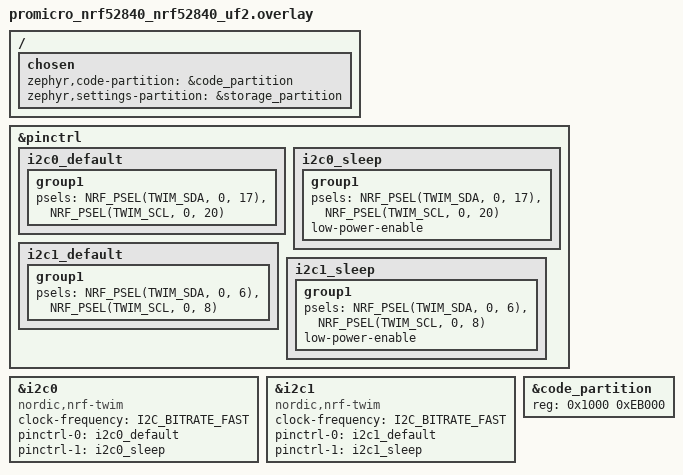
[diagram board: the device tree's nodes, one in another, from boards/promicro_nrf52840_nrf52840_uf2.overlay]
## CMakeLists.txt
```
#
# Copyright (c) 2019 Nordic Semiconductor ASA
#
# SPDX-License-Identifier: LicenseRef-Nordic-5-Clause
#
cmake_minimum_required(VERSION 3.20.0)

find_package(Zephyr REQUIRED HINTS $ENV{ZEPHYR_BASE})
project(peripheral_hids_mouse_Toast)

# Add all source files
target_sources(app PRIVATE
    src/main.c
    src/hid.c
    src/bluetooth.c
    src/encoder.c

)

target_include_directories(app PRIVATE src)
```

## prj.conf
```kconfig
#
# Copyright (c) 2019 Nordic Semiconductor ASA
#
# SPDX-License-Identifier: LicenseRef-Nordic-5-Clause
#
CONFIG_NCS_SAMPLES_DEFAULTS=y

CONFIG_BT=y
CONFIG_BT_MAX_CONN=2
CONFIG_BT_MAX_PAIRED=2
CONFIG_BT_ATT_TX_COUNT=5
CONFIG_BT_PERIPHERAL=y
CONFIG_BT_DEVICE_NAME="Wenke_Paddles"
CONFIG_BT_DEVICE_APPEARANCE=962

CONFIG_BT_BAS=y
CONFIG_BT_HIDS=y
CONFIG_BT_HIDS_MAX_CLIENT_COUNT=2
CONFIG_BT_HIDS_DEFAULT_PERM_RW_ENCRYPT=y
CONFIG_BT_GATT_UUID16_POOL_SIZE=40
CONFIG_BT_GATT_CHRC_POOL_SIZE=20

CONFIG_BT_CONN_CTX=y

CONFIG_BT_DIS=y
CONFIG_BT_DIS_MANUF_NAME=y
CONFIG_BT_DIS_MANUF_NAME_STR="NordicSemiconductor"
CONFIG_BT_DIS_PNP=y
CONFIG_BT_DIS_PNP_VID_SRC=2
CONFIG_BT_DIS_PNP_VID=0x1915
CONFIG_BT_DIS_PNP_PID=0xEEEE
CONFIG_BT_DIS_PNP_VER=0x0100

CONFIG_MAIN_STACK_SIZE=2048
CONFIG_SYSTEM_WORKQUEUE_STACK_SIZE=2048

# SERIAL LOGGING
CONFIG_SERIAL=y
CONFIG_UART_CONSOLE=y
CONFIG_CONSOLE=y#
# Copyright (c) 2019 Nordic Semiconductor ASA
#
# SPDX-License-Identifier: LicenseRef-Nordic-5-Clause
#
CONFIG_NCS_SAMPLES_DEFAULTS=y

CONFIG_BT=y
CONFIG_BT_MAX_CONN=1
CONFIG_BT_MAX_PAIRED=2
CONFIG_BT_ATT_TX_COUNT=5
CONFIG_BT_PERIPHERAL=y
CONFIG_BT_DEVICE_NAME="Wenke_Wheel"
CONFIG_BT_DEVICE_APPEARANCE=962

CONFIG_BT_BAS=y
CONFIG_BT_HIDS=y
CONFIG_BT_HIDS_MAX_CLIENT_COUNT=1
CONFIG_BT_HIDS_DEFAULT_PERM_RW_ENCRYPT=y
CONFIG_BT_GATT_UUID16_POOL_SIZE=40
CONFIG_BT_GATT_CHRC_POOL_SIZE=20

CONFIG_BT_CONN_CTX=y

CONFIG_BT_DIS=y
CONFIG_BT_DIS_MANUF_NAME=y
CONFIG_BT_DIS_MANUF_NAME_STR="NordicSemiconductor"
CONFIG_BT_DIS_PNP=y
CONFIG_BT_DIS_PNP_VID_SRC=2
CONFIG_BT_DIS_PNP_VID=0x1915
CONFIG_BT_DIS_PNP_PID=0xEEEE
CONFIG_BT_DIS_PNP_VER=0x0100

CONFIG_MAIN_STACK_SIZE=2048
CONFIG_SYSTEM_WORKQUEUE_STACK_SIZE=2048


# SERIAL LOGGING
CONFIG_SERIAL=y
CONFIG_UART_CONSOLE=y
CONFIG_CONSOLE=y
CONFIG_LOG=y
CONFIG_LOG_BACKEND_UART=y
CONFIG_LOG_DEFAULT_LEVEL=3
CONFIG_USB_CDC_ACM=y
CONFIG_USB_COMPOSITE_DEVICE=y
# ##############

# I2C CONFIGS
CONFIG_I2C=y
CONFIG_GPIO=y
CONFIG_LOG=y
CONFIG_LOG_BACKEND_UART=y
CONFIG_LOG_DEFAULT_LEVEL=3
CONFIG_USB_CDC_ACM=y
CONFIG_USB_COMPOSITE_DEVICE=y
# ##############

# I2C CONFIGS
CONFIG_I2C=y
CONFIG_GPIO=y
```

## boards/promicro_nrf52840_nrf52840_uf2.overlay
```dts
/* I2C0 - First encoder: SDA P0.17, SCL P0.20 */
&pinctrl {
    i2c0_default: i2c0_default {
        group1 {
            psels = <NRF_PSEL(TWIM_SDA, 0, 17)>,
                    <NRF_PSEL(TWIM_SCL, 0, 20)>;
        };
    };

    i2c0_sleep: i2c0_sleep {
        group1 {
            psels = <NRF_PSEL(TWIM_SDA, 0, 17)>,
                    <NRF_PSEL(TWIM_SCL, 0, 20)>;
            low-power-enable;
        };
    };

    /* I2C1 - Second encoder: SDA P0.06, SCL P0.08 */
    i2c1_default: i2c1_default {
        group1 {
            psels = <NRF_PSEL(TWIM_SDA, 0, 6)>,
                    <NRF_PSEL(TWIM_SCL, 0, 8)>;
        };
    };

    i2c1_sleep: i2c1_sleep {
        group1 {
            psels = <NRF_PSEL(TWIM_SDA, 0, 6)>,
                    <NRF_PSEL(TWIM_SCL, 0, 8)>;
            low-power-enable;
        };
    };
};

&i2c0 {
    compatible = "nordic,nrf-twim";
    status = "okay";
    clock-frequency = <I2C_BITRATE_FAST>;
    pinctrl-0 = <&i2c0_default>;
    pinctrl-1 = <&i2c0_sleep>;
    pinctrl-names = "default", "sleep";
};

&i2c1 {
    compatible = "nordic,nrf-twim";
    status = "okay";
    clock-frequency = <I2C_BITRATE_FAST>;
    pinctrl-0 = <&i2c1_default>;
    pinctrl-1 = <&i2c1_sleep>;
    pinctrl-names = "default", "sleep";
};

/* Remove the SoftDevice partition and fix the code partition offset */
/delete-node/ &reserved_partition_0;

&code_partition {
    reg = <0x1000 0xEB000>;  /* Start at 0x1000 instead of 0x26000 */
};

/ {
    chosen {
        zephyr,code-partition = &code_partition;
        zephyr,settings-partition = &storage_partition;
    };
};
```

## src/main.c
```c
/*
 * Copyright (c) 2018 Nordic Semiconductor ASA
 *
 * SPDX-License-Identifier: LicenseRef-Nordic-5-Clause
 */

#include <zephyr/kernel.h>
#include <zephyr/sys/printk.h>
#include <zephyr/bluetooth/services/bas.h>

#include "bluetooth.h"
#include "hid.h"
#include "encoder.h"

#define DEVICE_NAME CONFIG_BT_DEVICE_NAME
#define POLL_INTERVAL_MS 10

/* Scroll tuning parameters - adjust these to taste */
#define SCROLL_DEADZONE      25    // Ignore offsets smaller than this (noise filter)
#define SCROLL_DIVISOR       75   // Higher = slower scroll, lower = faster
#define SCROLL_MAX           127    // Maximum scroll value per tick (caps speed)

/**
 * @brief Convert encoder offset to scroll value
 * 
 * Maps the absolute offset from reference position to a scroll speed.
 * Larger offset = faster scroll. Includes deadzone and clamping.
 * 
 * @param offset Raw encoder offset from reference
 * @return Scroll value to send (-SCROLL_MAX to +SCROLL_MAX), 0 if in deadzone
 */
static int8_t offset_to_scroll(int32_t offset)
{
    /* Deadzone - ignore small movements */
    if (offset > -SCROLL_DEADZONE && offset < SCROLL_DEADZONE) {
        return 0;
    }

    /* Remove deadzone from calculation */
    int32_t adjusted;
    if (offset > 0) {
        adjusted = offset - SCROLL_DEADZONE;
    } else {
        adjusted = offset + SCROLL_DEADZONE;
    }

    /* Apply acceleration curve */
    int32_t scroll;
    int32_t abs_adjusted = adjusted < 0 ? -adjusted : adjusted;
    int32_t sign = adjusted < 0 ? -1 : 1;
    
    /* Linear base + quadratic acceleration */
    int32_t linear = abs_adjusted / SCROLL_DIVISOR;
    int32_t accel = (abs_adjusted * abs_adjusted) / (SCROLL_DIVISOR * 1000);
    
    scroll = sign * (linear + accel);

    /* Clamp to max scroll speed */
    if (scroll > SCROLL_MAX) {
        scroll = SCROLL_MAX;
    } else if (scroll < -SCROLL_MAX) {
        scroll = -SCROLL_MAX;
    }

    return (int8_t)scroll;
}

int main(void)
{
    k_sleep(K_MSEC(3000));  // buffer
    int err;

    printk("Starting Bluetooth Peripheral HIDS mouse sample\n");
    printk("Board: nice!nano / Pro Micro nRF52840\n");

    /* Initialize HID service */
    hid_init();
    
    /* Initialize rotary encoder */
    err = encoder_init();
    if (err) {
        printk("Failed to initialize encoder (err %d)\n", err);
        return 0;
    }

    /* Initialize Bluetooth stack and start advertising */
    err = bluetooth_init(DEVICE_NAME);
    if (err) {
        printk("Bluetooth initialization failed (err %d)\n", err);
        return 0;
    }

    printk("Device ready - advertising as '%s'\n", DEVICE_NAME);
    printk("Waiting for connection...\n");

    /* Main loop */
    while (1) {
        int32_t delta;
        encoder_read_delta(&delta);
        
        int8_t wheel = offset_to_scroll(delta);
        
        if (wheel != 0) {
            hid_mouse_scroll_send(wheel, 0);
        }
        
        k_sleep(K_MSEC(POLL_INTERVAL_MS));
    }

    return 0;
}
```

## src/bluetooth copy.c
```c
/*
 * Copyright (c) 2018 Nordic Semiconductor ASA
 *
 * SPDX-License-Identifier: LicenseRef-Nordic-5-Clause
 */

#include <zephyr/types.h>
#include <string.h>
#include <zephyr/sys/printk.h>
#include <zephyr/kernel.h>
#include <zephyr/settings/settings.h>

#include <zephyr/bluetooth/bluetooth.h>
#include <zephyr/bluetooth/hci.h>
#include <zephyr/bluetooth/conn.h>
#include <zephyr/bluetooth/uuid.h>
#include <zephyr/bluetooth/gatt.h>
#include <zephyr/bluetooth/services/bas.h>

#include "bluetooth.h"
#include "hid.h"

static struct bt_conn *connections[CONFIG_BT_HIDS_MAX_CLIENT_COUNT];
static volatile bool is_adv_running;
static struct k_work adv_work;
static const char *device_name;
static size_t device_name_len;

#if CONFIG_BT_DIRECTED_ADVERTISING
K_MSGQ_DEFINE(bonds_queue, sizeof(bt_addr_le_t), CONFIG_BT_MAX_PAIRED, 4);

static void bond_find(const struct bt_bond_info *info, void *user_data)
{
	int err;

	/* Filter already connected peers */
	for (size_t i = 0; i < CONFIG_BT_HIDS_MAX_CLIENT_COUNT; i++) {
		if (connections[i]) {
			const bt_addr_le_t *dst = bt_conn_get_dst(connections[i]);
			if (!bt_addr_le_cmp(&info->addr, dst)) {
				return;
			}
		}
	}

	err = k_msgq_put(&bonds_queue, (void *)&info->addr, K_NO_WAIT);
	if (err) {
		printk("No space in the queue for the bond.\n");
	}
}
#endif

/* Advertising data - must be at file scope */
static const struct bt_data ad[] = {
	BT_DATA_BYTES(BT_DATA_GAP_APPEARANCE,
		      (CONFIG_BT_DEVICE_APPEARANCE >> 0) & 0xff,
		      (CONFIG_BT_DEVICE_APPEARANCE >> 8) & 0xff),
	BT_DATA_BYTES(BT_DATA_FLAGS, (BT_LE_AD_GENERAL | BT_LE_AD_NO_BREDR)),
	BT_DATA_BYTES(BT_DATA_UUID16_ALL, 
		      BT_UUID_16_ENCODE(BT_UUID_HIDS_VAL),
		      BT_UUID_16_ENCODE(BT_UUID_BAS_VAL)),
};

static void advertising_continue(void)
{
	struct bt_le_adv_param adv_param;

#if CONFIG_BT_DIRECTED_ADVERTISING
	bt_addr_le_t addr;

	if (!k_msgq_get(&bonds_queue, &addr, K_NO_WAIT)) {
		char addr_buf[BT_ADDR_LE_STR_LEN];
		int err;

		if (is_adv_running) {
			err = bt_le_adv_stop();
			if (err) {
				printk("Advertising failed to stop (err %d)\n", err);
				return;
			}
			is_adv_running = false;
		}

		adv_param = *BT_LE_ADV_CONN_DIR(&addr);
		adv_param.options |= BT_LE_ADV_OPT_DIR_ADDR_RPA;

		err = bt_le_adv_start(&adv_param, NULL, 0, NULL, 0);
		if (err) {
			printk("Directed advertising failed to start (err %d)\n", err);
			return;
		}

		bt_addr_le_to_str(&addr, addr_buf, BT_ADDR_LE_STR_LEN);
		printk("Direct advertising to %s started\n", addr_buf);
	} else
#endif
	{
		int err;

		if (is_adv_running) {
			return;
		}

		/* Scan response data with device name */
		struct bt_data sd[] = {
			BT_DATA(BT_DATA_NAME_COMPLETE, device_name, device_name_len),
		};

		adv_param = *BT_LE_ADV_CONN_FAST_2;
		err = bt_le_adv_start(&adv_param, ad, ARRAY_SIZE(ad), sd, ARRAY_SIZE(sd));
		if (err) {
			printk("Advertising failed to start (err %d)\n", err);
			return;
		}

		printk("Regular advertising started\n");
	}

	is_adv_running = true;
}

static void advertising_start(void)
{
#if CONFIG_BT_DIRECTED_ADVERTISING
	k_msgq_purge(&bonds_queue);
	bt_foreach_bond(BT_ID_DEFAULT, bond_find, NULL);
#endif

	k_work_submit(&adv_work);
}

static void advertising_process(struct k_work *work)
{
	advertising_continue();
}

static void insert_conn_object(struct bt_conn *conn)
{
	for (size_t i = 0; i < CONFIG_BT_HIDS_MAX_CLIENT_COUNT; i++) {
		if (!connections[i]) {
			connections[i] = conn;
			return;
		}
	}

	printk("Connection object could not be inserted %p\n", conn);
}

static void remove_conn_object(struct bt_conn *conn)
{
	for (size_t i = 0; i < CONFIG_BT_HIDS_MAX_CLIENT_COUNT; i++) {
		if (connections[i] == conn) {
			connections[i] = NULL;
			break;
		}
	}
}

bool bluetooth_is_conn_slot_free(void)
{
	for (size_t i = 0; i < CONFIG_BT_HIDS_MAX_CLIENT_COUNT; i++) {
		if (!connections[i]) {
			return true;
		}
	}
	return false;
}

struct bt_conn *bluetooth_get_conn(size_t index)
{
	if (index < CONFIG_BT_HIDS_MAX_CLIENT_COUNT) {
		return connections[index];
	}
	return NULL;
}

static void connected(struct bt_conn *conn, uint8_t err)
{
	char addr[BT_ADDR_LE_STR_LEN];

	is_adv_running = false;
	bt_addr_le_to_str(bt_conn_get_dst(conn), addr, sizeof(addr));

	if (err) {
		if (err == BT_HCI_ERR_ADV_TIMEOUT) {
			printk("Direct advertising to %s timed out\n", addr);
			k_work_submit(&adv_work);
		} else {
			printk("Failed to connect to %s 0x%02x %s\n", 
			       addr, err, bt_hci_err_to_str(err));
		}
		return;
	}

	printk("Connected %s\n", addr);

	/* Notify HID service */
	err = hid_notify_connected(conn);
	if (err) {
		printk("Failed to notify HID service about connection\n");
		return;
	}

	insert_conn_object(conn);

	struct bt_conn_info info;
	bt_conn_get_info(conn, &info);
	
	printk("Initial connection parameters:\n");
	printk("  Interval: %u (%.2f ms)\n", 
	       info.le.interval, info.le.interval * 1.25);
	printk("  Latency: %u\n", info.le.latency);
	printk("  Timeout: %u\n", info.le.timeout);

	if (bluetooth_is_conn_slot_free()) {
		advertising_start();
	}
}

static void disconnected(struct bt_conn *conn, uint8_t reason)
{
	char addr[BT_ADDR_LE_STR_LEN];

	bt_addr_le_to_str(bt_conn_get_dst(conn), addr, sizeof(addr));
	printk("Disconnected from %s, reason 0x%02x %s\n", 
	       addr, reason, bt_hci_err_to_str(reason));


	/* Notify HID service */
	int err = hid_notify_disconnected(conn);
	if (err) {
		printk("Failed to notify HID service about disconnection\n");
	}

	remove_conn_object(conn);
	advertising_start();
}

#ifdef CONFIG_BT_HIDS_SECURITY_ENABLED
static void security_changed(struct bt_conn *conn, bt_security_t level,
			     enum bt_security_err err)
{
	char addr[BT_ADDR_LE_STR_LEN];

	bt_addr_le_to_str(bt_conn_get_dst(conn), addr, sizeof(addr));

	if (!err) {
		printk("Security changed: %s level %u\n", addr, level);

	} else {
		printk("Security failed: %s level %u err %d %s\n", 
		       addr, level, err, bt_security_err_to_str(err));
	}
}
#endif

BT_CONN_CB_DEFINE(conn_callbacks) = {
	.connected = connected,
	.disconnected = disconnected,
#ifdef CONFIG_BT_HIDS_SECURITY_ENABLED
	.security_changed = security_changed,
#endif
};

/* Authentication callbacks */
#if defined(CONFIG_BT_HIDS_SECURITY_ENABLED)
static void auth_passkey_display(struct bt_conn *conn, unsigned int passkey)
{
	char addr[BT_ADDR_LE_STR_LEN];

	bt_addr_le_to_str(bt_conn_get_dst(conn), addr, sizeof(addr));
	printk("Passkey for %s: %06u\n", addr, passkey);
}

static void auth_passkey_confirm(struct bt_conn *conn, unsigned int passkey)
{
	char addr[BT_ADDR_LE_STR_LEN];

	bt_addr_le_to_str(bt_conn_get_dst(conn), addr, sizeof(addr));
	printk("Auto-accepting pairing for %s: %06u\n", addr, passkey);
	
	bt_conn_auth_passkey_confirm(conn);
}

static void auth_cancel(struct bt_conn *conn)
{
	char addr[BT_ADDR_LE_STR_LEN];

	bt_addr_le_to_str(bt_conn_get_dst(conn), addr, sizeof(addr));
	printk("Pairing cancelled: %s\n", addr);
}

static void pairing_complete(struct bt_conn *conn, bool bonded)
{
	char addr[BT_ADDR_LE_STR_LEN];

	bt_addr_le_to_str(bt_conn_get_dst(conn), addr, sizeof(addr));
	printk("Pairing completed: %s, bonded: %d\n", addr, bonded);
}

static void pairing_failed(struct bt_conn *conn, enum bt_security_err reason)
{
	char addr[BT_ADDR_LE_STR_LEN];

	bt_addr_le_to_str(bt_conn_get_dst(conn), addr, sizeof(addr));
	printk("Pairing failed conn: %s, reason %d %s\n", 
	       addr, reason, bt_security_err_to_str(reason));
}

static struct bt_conn_auth_cb conn_auth_callbacks = {
	.passkey_display = auth_passkey_display,
	.passkey_confirm = auth_passkey_confirm,
	.cancel = auth_cancel,
};

static struct bt_conn_auth_info_cb conn_auth_info_callbacks = {
	.pairing_complete = pairing_complete,
	.pairing_failed = pairing_failed
};
#else
static struct bt_conn_auth_cb conn_auth_callbacks;
static struct bt_conn_auth_info_cb conn_auth_info_callbacks;
#endif

int bluetooth_init(const char *name)
{
	int err;

	device_name = name;
	device_name_len = strlen(name);

	/* Register authentication callbacks */
	if (IS_ENABLED(CONFIG_BT_HIDS_SECURITY_ENABLED)) {
		err = bt_conn_auth_cb_register(&conn_auth_callbacks);
		if (err) {
			printk("Failed to register authorization callbacks.\n");
			return err;
		}

		err = bt_conn_auth_info_cb_register(&conn_auth_info_callbacks);
		if (err) {
			printk("Failed to register authorization info callbacks.\n");
			return err;
		}
	}

	/* Enable Bluetooth */
	err = bt_enable(NULL);
	if (err) {
		printk("Bluetooth init failed (err %d)\n", err);
		return err;
	}

	printk("Bluetooth initialized\n");

	/* Initialize work queues */
	k_work_init(&adv_work, advertising_process);

	/* Load settings if enabled */
	if (IS_ENABLED(CONFIG_SETTINGS)) {
		settings_load();
	}

	/* Start advertising */
	advertising_start();

	return 0;
}
```

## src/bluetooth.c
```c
/*
 * Copyright (c) 2018 Nordic Semiconductor ASA
 *
 * SPDX-License-Identifier: LicenseRef-Nordic-5-Clause
 */

#include <zephyr/types.h>
#include <string.h>
#include <zephyr/sys/printk.h>
#include <zephyr/kernel.h>
#include <zephyr/settings/settings.h>

#include <zephyr/bluetooth/bluetooth.h>
#include <zephyr/bluetooth/hci.h>
#include <zephyr/bluetooth/conn.h>
#include <zephyr/bluetooth/uuid.h>
#include <zephyr/bluetooth/gatt.h>
#include <zephyr/bluetooth/services/bas.h>

#include <zephyr/drivers/gpio.h>

#include "bluetooth.h"
#include "hid.h"

/* Bluetooth connection management */
static struct bt_conn *connections[CONFIG_BT_HIDS_MAX_CLIENT_COUNT];
static volatile bool is_adv_running;
static struct k_work adv_work;
static const char *device_name;
static size_t device_name_len;

/* Unpair button configuration */
#define UNPAIR_BUTTON_PIN 10
static const struct device *button_dev;
static struct gpio_callback button_cb_data;
static struct k_work unpair_work;

#if CONFIG_BT_DIRECTED_ADVERTISING
K_MSGQ_DEFINE(bonds_queue, sizeof(bt_addr_le_t), CONFIG_BT_MAX_PAIRED, 4);

static void bond_find(const struct bt_bond_info *info, void *user_data)
{
	int err;

	/* Filter already connected peers */
	for (size_t i = 0; i < CONFIG_BT_HIDS_MAX_CLIENT_COUNT; i++) {
		if (connections[i]) {
			const bt_addr_le_t *dst = bt_conn_get_dst(connections[i]);
			if (!bt_addr_le_cmp(&info->addr, dst)) {
				return;
			}
		}
	}

	err = k_msgq_put(&bonds_queue, (void *)&info->addr, K_NO_WAIT);
	if (err) {
		printk("No space in the queue for the bond.\n");
	}
}
#endif

/* Advertising data - must be at file scope */
static const struct bt_data ad[] = {
	BT_DATA_BYTES(BT_DATA_GAP_APPEARANCE,
		      (CONFIG_BT_DEVICE_APPEARANCE >> 0) & 0xff,
		      (CONFIG_BT_DEVICE_APPEARANCE >> 8) & 0xff),
	BT_DATA_BYTES(BT_DATA_FLAGS, (BT_LE_AD_GENERAL | BT_LE_AD_NO_BREDR)),
	BT_DATA_BYTES(BT_DATA_UUID16_ALL, 
		      BT_UUID_16_ENCODE(BT_UUID_HIDS_VAL),
		      BT_UUID_16_ENCODE(BT_UUID_BAS_VAL)),
};

static void advertising_continue(void)
{
	struct bt_le_adv_param adv_param;

#if CONFIG_BT_DIRECTED_ADVERTISING
	bt_addr_le_t addr;

	if (!k_msgq_get(&bonds_queue, &addr, K_NO_WAIT)) {
		char addr_buf[BT_ADDR_LE_STR_LEN];
		int err;

		if (is_adv_running) {
			err = bt_le_adv_stop();
			if (err) {
				printk("Advertising failed to stop (err %d)\n", err);
				return;
			}
			is_adv_running = false;
		}

		adv_param = *BT_LE_ADV_CONN_DIR(&addr);
		adv_param.options |= BT_LE_ADV_OPT_DIR_ADDR_RPA;

		err = bt_le_adv_start(&adv_param, NULL, 0, NULL, 0);
		if (err) {
			printk("Directed advertising failed to start (err %d)\n", err);
			return;
		}

		bt_addr_le_to_str(&addr, addr_buf, BT_ADDR_LE_STR_LEN);
		printk("Direct advertising to %s started\n", addr_buf);
	} else
#endif
	{
		int err;

		if (is_adv_running) {
			return;
		}

		/* Scan response data with device name */
		struct bt_data sd[] = {
			BT_DATA(BT_DATA_NAME_COMPLETE, device_name, device_name_len),
		};

		adv_param = *BT_LE_ADV_CONN_FAST_2;
		err = bt_le_adv_start(&adv_param, ad, ARRAY_SIZE(ad), sd, ARRAY_SIZE(sd));
		if (err) {
			printk("Advertising failed to start (err %d)\n", err);
			return;
		}

		printk("Regular advertising started\n");
	}

	is_adv_running = true;
}

static void advertising_start(void)
{
#if CONFIG_BT_DIRECTED_ADVERTISING
	k_msgq_purge(&bonds_queue);
	bt_foreach_bond(BT_ID_DEFAULT, bond_find, NULL);
#endif

	k_work_submit(&adv_work);
}

static void advertising_process(struct k_work *work)
{
	advertising_continue();
}

static void insert_conn_object(struct bt_conn *conn)
{
	for (size_t i = 0; i < CONFIG_BT_HIDS_MAX_CLIENT_COUNT; i++) {
		if (!connections[i]) {
			connections[i] = conn;
			return;
		}
	}

	printk("Connection object could not be inserted %p\n", conn);
}

static void remove_conn_object(struct bt_conn *conn)
{
	for (size_t i = 0; i < CONFIG_BT_HIDS_MAX_CLIENT_COUNT; i++) {
		if (connections[i] == conn) {
			connections[i] = NULL;
			break;
		}
	}
}

bool bluetooth_is_conn_slot_free(void)
{
	for (size_t i = 0; i < CONFIG_BT_HIDS_MAX_CLIENT_COUNT; i++) {
		if (!connections[i]) {
			return true;
		}
	}
	return false;
}

struct bt_conn *bluetooth_get_conn(size_t index)
{
	if (index < CONFIG_BT_HIDS_MAX_CLIENT_COUNT) {
		return connections[index];
	}
	return NULL;
}

static void connected(struct bt_conn *conn, uint8_t err)
{
	char addr[BT_ADDR_LE_STR_LEN];

	is_adv_running = false;
	bt_addr_le_to_str(bt_conn_get_dst(conn), addr, sizeof(addr));

	if (err) {
		if (err == BT_HCI_ERR_ADV_TIMEOUT) {
			printk("Direct advertising to %s timed out\n", addr);
			k_work_submit(&adv_work);
		} else {
			printk("Failed to connect to %s 0x%02x %s\n", 
			       addr, err, bt_hci_err_to_str(err));
		}
		return;
	}

	printk("Connected %s\n", addr);

	/* Notify HID service */
	err = hid_notify_connected(conn);
	if (err) {
		printk("Failed to notify HID service about connection\n");
		return;
	}

	insert_conn_object(conn);

	struct bt_conn_info info;
	bt_conn_get_info(conn, &info);
	
	printk("Initial connection parameters:\n");
	printk("  Interval: %u (%.2f ms)\n", 
	       info.le.interval, info.le.interval * 1.25);
	printk("  Latency: %u\n", info.le.latency);
	printk("  Timeout: %u\n", info.le.timeout);

	if (bluetooth_is_conn_slot_free()) {
		advertising_start();
	}
}

static void disconnected(struct bt_conn *conn, uint8_t reason)
{
	char addr[BT_ADDR_LE_STR_LEN];

	bt_addr_le_to_str(bt_conn_get_dst(conn), addr, sizeof(addr));
	printk("Disconnected from %s, reason 0x%02x %s\n", 
	       addr, reason, bt_hci_err_to_str(reason));

	/* Notify HID service */
	int err = hid_notify_disconnected(conn);
	if (err) {
		printk("Failed to notify HID service about disconnection\n");
	}

	remove_conn_object(conn);
	advertising_start();
}

#ifdef CONFIG_BT_HIDS_SECURITY_ENABLED
static void security_changed(struct bt_conn *conn, bt_security_t level,
			     enum bt_security_err err)
{
	char addr[BT_ADDR_LE_STR_LEN];

	bt_addr_le_to_str(bt_conn_get_dst(conn), addr, sizeof(addr));

	if (!err) {
		printk("Security changed: %s level %u\n", addr, level);
	} else {
		printk("Security failed: %s level %u err %d %s\n", 
		       addr, level, err, bt_security_err_to_str(err));
	}
}
#endif

BT_CONN_CB_DEFINE(conn_callbacks) = {
	.connected = connected,
	.disconnected = disconnected,
#ifdef CONFIG_BT_HIDS_SECURITY_ENABLED
	.security_changed = security_changed,
#endif
};

/* Authentication callbacks */
#if defined(CONFIG_BT_HIDS_SECURITY_ENABLED)
static void auth_passkey_display(struct bt_conn *conn, unsigned int passkey)
{
	char addr[BT_ADDR_LE_STR_LEN];

	bt_addr_le_to_str(bt_conn_get_dst(conn), addr, sizeof(addr));
	printk("Passkey for %s: %06u\n", addr, passkey);
}

static void auth_passkey_confirm(struct bt_conn *conn, unsigned int passkey)
{
	char addr[BT_ADDR_LE_STR_LEN];

	bt_addr_le_to_str(bt_conn_get_dst(conn), addr, sizeof(addr));
	printk("Auto-accepting pairing for %s: %06u\n", addr, passkey);
	
	bt_conn_auth_passkey_confirm(conn);
}

static void auth_cancel(struct bt_conn *conn)
{
	char addr[BT_ADDR_LE_STR_LEN];

	bt_addr_le_to_str(bt_conn_get_dst(conn), addr, sizeof(addr));
	printk("Pairing cancelled: %s\n", addr);
}

static void pairing_complete(struct bt_conn *conn, bool bonded)
{
	char addr[BT_ADDR_LE_STR_LEN];

	bt_addr_le_to_str(bt_conn_get_dst(conn), addr, sizeof(addr));
	printk("Pairing completed: %s, bonded: %d\n", addr, bonded);
}

static void pairing_failed(struct bt_conn *conn, enum bt_security_err reason)
{
	char addr[BT_ADDR_LE_STR_LEN];

	bt_addr_le_to_str(bt_conn_get_dst(conn), addr, sizeof(addr));
	printk("Pairing failed conn: %s, reason %d %s\n", 
	       addr, reason, bt_security_err_to_str(reason));
}

static struct bt_conn_auth_cb conn_auth_callbacks = {
	.passkey_display = auth_passkey_display,
	.passkey_confirm = auth_passkey_confirm,
	.cancel = auth_cancel,
};

static struct bt_conn_auth_info_cb conn_auth_info_callbacks = {
	.pairing_complete = pairing_complete,
	.pairing_failed = pairing_failed
};
#else
static struct bt_conn_auth_cb conn_auth_callbacks;
static struct bt_conn_auth_info_cb conn_auth_info_callbacks;
#endif

/* Unpair button implementation */
static void unpair_all_bonds(struct k_work *work)
{
	int err;
	
	printk("=== UNPAIR BUTTON PRESSED ===\n");
	printk("Unpairing all bonded devices...\n");
	
	/* Disconnect all active connections first */
	for (size_t i = 0; i < CONFIG_BT_HIDS_MAX_CLIENT_COUNT; i++) {
		if (connections[i]) {
			char addr[BT_ADDR_LE_STR_LEN];
			bt_addr_le_to_str(bt_conn_get_dst(connections[i]), addr, sizeof(addr));
			printk("Disconnecting %s...\n", addr);
			
			err = bt_conn_disconnect(connections[i], 
			                         BT_HCI_ERR_REMOTE_USER_TERM_CONN);
			if (err) {
				printk("Failed to disconnect connection %zu (err %d)\n", 
				       i, err);
			}
		}
	}
	
	/* Wait for disconnections to complete */
	k_sleep(K_MSEC(100));
	
	/* Clear all bonds */
	err = bt_unpair(BT_ID_DEFAULT, NULL);
	if (err) {
		printk("Failed to unpair devices (err %d)\n", err);
	} else {
		printk("All devices unpaired successfully!\n");
	}
	
	/* Restart advertising */
	k_sleep(K_MSEC(500));
	advertising_start();
	
	printk("=== UNPAIR COMPLETE ===\n");
}

static void button_pressed(const struct device *dev, 
                          struct gpio_callback *cb, 
                          uint32_t pins)
{
	printk(">>> Unpair button interrupt triggered! <<<\n");
	k_work_submit(&unpair_work);
}

static int unpair_button_init(void)
{
	int err;
	
	printk("\n=== Initializing Unpair Button ===\n");
	
	/* Get GPIO device */
	button_dev = DEVICE_DT_GET(DT_NODELABEL(gpio0));
	
	if (!button_dev) {
		printk("ERROR: Failed to get GPIO device\n");
		return -ENODEV;
	}
	
	printk("GPIO device pointer: %p\n", button_dev);
	
	if (!device_is_ready(button_dev)) {
		printk("ERROR: GPIO device not ready\n");
		return -ENODEV;
	}
	
	printk("GPIO device ready: %s\n", button_dev->name);
	
	/* Configure pin as input with pull-up */
	err = gpio_pin_configure(button_dev, UNPAIR_BUTTON_PIN, 
	                         GPIO_INPUT | GPIO_PULL_UP);
	if (err) {
		printk("ERROR: Failed to configure pin P0.%02d (err %d)\n", 
		       UNPAIR_BUTTON_PIN, err);
		return err;
	}
	
	printk("Pin P0.%02d configured as input with pull-up\n", UNPAIR_BUTTON_PIN);
	
	/* Test pin reading */
	int pin_state = gpio_pin_get(button_dev, UNPAIR_BUTTON_PIN);
	printk("Current pin state: %d (should be 1 when not pressed)\n", pin_state);
	
	/* Configure interrupt on falling edge (button press) */
	err = gpio_pin_interrupt_configure(button_dev, UNPAIR_BUTTON_PIN,
	                                   GPIO_INT_EDGE_FALLING);
	if (err) {
		printk("ERROR: Failed to configure interrupt (err %d)\n", err);
		return err;
	}
	
	printk("Interrupt configured for falling edge\n");
	
	/* Setup and add callback */
	gpio_init_callback(&button_cb_data, button_pressed, BIT(UNPAIR_BUTTON_PIN));
	err = gpio_add_callback(button_dev, &button_cb_data);
	if (err) {
		printk("ERROR: Failed to add callback (err %d)\n", err);
		return err;
	}
	
	printk("GPIO callback added\n");
	
	/* Initialize work queue */
	k_work_init(&unpair_work, unpair_all_bonds);
	
	printk("✓ Unpair button successfully initialized on P0.09\n");
	printk("  Press button to unpair all devices\n");
	printk("=================================\n\n");
	
	return 0;
}

int bluetooth_init(const char *name)
{
	int err;

	printk("\n=== Bluetooth Initialization Start ===\n");

	device_name = name;
	device_name_len = strlen(name);

	/* Register authentication callbacks */
	if (IS_ENABLED(CONFIG_BT_HIDS_SECURITY_ENABLED)) {
		err = bt_conn_auth_cb_register(&conn_auth_callbacks);
		if (err) {
			printk("Failed to register authorization callbacks.\n");
			return err;
		}

		err = bt_conn_auth_info_cb_register(&conn_auth_info_callbacks);
		if (err) {
			printk("Failed to register authorization info callbacks.\n");
			return err;
		}
	}

	/* Enable Bluetooth */
	err = bt_enable(NULL);
	if (err) {
		printk("Bluetooth init failed (err %d)\n", err);
		return err;
	}

	printk("Bluetooth initialized\n");

	/* Initialize work queues */
	k_work_init(&adv_work, advertising_process);

	/* Load settings if enabled */
	if (IS_ENABLED(CONFIG_SETTINGS)) {
		settings_load();
	}

	/* Initialize unpair button */
	err = unpair_button_init();
	if (err) {
		printk("WARNING: Failed to initialize unpair button (err %d)\n", err);
		printk("Continuing without unpair button functionality...\n");
		/* Non-fatal, continue */
	}

	/* Start advertising */
	advertising_start();

	printk("=== Bluetooth Initialization Complete ===\n\n");

	return 0;
}
```

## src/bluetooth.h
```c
/*
 * Copyright (c) 2018 Nordic Semiconductor ASA
 *
 * SPDX-License-Identifier: LicenseRef-Nordic-5-Clause
 */

#ifndef BLUETOOTH_H_
#define BLUETOOTH_H_

#include <zephyr/bluetooth/conn.h>

/**
 * @brief Initialize Bluetooth stack and start advertising
 * 
 * @param device_name Name to advertise
 * @return 0 on success, negative errno on failure
 */
int bluetooth_init(const char *device_name);

/**
 * @brief Check if a connection slot is available
 * 
 * @return true if a slot is free, false otherwise
 */
bool bluetooth_is_conn_slot_free(void);

/**
 * @brief Get connection by index
 * 
 * @param index Connection index
 * @return Pointer to connection or NULL
 */
struct bt_conn *bluetooth_get_conn(size_t index);


/**
 * @brief Check if a connected
 * 
 * @return true if a security passed, and device connected.
 */
bool bluetooth_security_passed(void);

#endif /* BLUETOOTH_H_ */
```

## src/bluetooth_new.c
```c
/*
 * Copyright (c) 2018 Nordic Semiconductor ASA
 *
 * SPDX-License-Identifier: LicenseRef-Nordic-5-Clause
 */

#include <zephyr/types.h>
#include <string.h>
#include <zephyr/sys/printk.h>
#include <zephyr/kernel.h>
#include <zephyr/settings/settings.h>

#include <zephyr/bluetooth/bluetooth.h>
#include <zephyr/bluetooth/hci.h>
#include <zephyr/bluetooth/conn.h>
#include <zephyr/bluetooth/uuid.h>
#include <zephyr/bluetooth/gatt.h>
#include <zephyr/bluetooth/services/bas.h>

#include "bluetooth.h"
#include "hid.h"

static struct bt_conn *connections[CONFIG_BT_HIDS_MAX_CLIENT_COUNT];
static volatile bool is_adv_running;
static struct k_work adv_work;
static const char *device_name;
static size_t device_name_len;

bool is_security_passed = false;

#if CONFIG_BT_DIRECTED_ADVERTISING
K_MSGQ_DEFINE(bonds_queue, sizeof(bt_addr_le_t), CONFIG_BT_MAX_PAIRED, 4);

static void bond_find(const struct bt_bond_info *info, void *user_data)
{
	int err;

	/* Filter already connected peers */
	for (size_t i = 0; i < CONFIG_BT_HIDS_MAX_CLIENT_COUNT; i++) {
		if (connections[i]) {
			const bt_addr_le_t *dst = bt_conn_get_dst(connections[i]);
			if (!bt_addr_le_cmp(&info->addr, dst)) {
				return;
			}
		}
	}

	err = k_msgq_put(&bonds_queue, (void *)&info->addr, K_NO_WAIT);
	if (err) {
		printk("No space in the queue for the bond.\n");
	}
}
#endif

/* Advertising data - must be at file scope */
static const struct bt_data ad[] = {
	BT_DATA_BYTES(BT_DATA_GAP_APPEARANCE,
		      (CONFIG_BT_DEVICE_APPEARANCE >> 0) & 0xff,
		      (CONFIG_BT_DEVICE_APPEARANCE >> 8) & 0xff),
	BT_DATA_BYTES(BT_DATA_FLAGS, (BT_LE_AD_GENERAL | BT_LE_AD_NO_BREDR)),
	BT_DATA_BYTES(BT_DATA_UUID16_ALL, 
		      BT_UUID_16_ENCODE(BT_UUID_HIDS_VAL),
		      BT_UUID_16_ENCODE(BT_UUID_BAS_VAL)),
};

static void advertising_continue(void)
{
	struct bt_le_adv_param adv_param;

#if CONFIG_BT_DIRECTED_ADVERTISING
	bt_addr_le_t addr;

	if (!k_msgq_get(&bonds_queue, &addr, K_NO_WAIT)) {
		char addr_buf[BT_ADDR_LE_STR_LEN];
		int err;

		if (is_adv_running) {
			err = bt_le_adv_stop();
			if (err) {
				printk("Advertising failed to stop (err %d)\n", err);
				return;
			}
			is_adv_running = false;
		}

		adv_param = *BT_LE_ADV_CONN_DIR(&addr);
		adv_param.options |= BT_LE_ADV_OPT_DIR_ADDR_RPA;

		err = bt_le_adv_start(&adv_param, NULL, 0, NULL, 0);
		if (err) {
			printk("Directed advertising failed to start (err %d)\n", err);
			return;
		}

		bt_addr_le_to_str(&addr, addr_buf, BT_ADDR_LE_STR_LEN);
		printk("Direct advertising to %s started\n", addr_buf);
	} else
#endif
	{
		int err;

		if (is_adv_running) {
			return;
		}

		/* Scan response data with device name */
		struct bt_data sd[] = {
			BT_DATA(BT_DATA_NAME_COMPLETE, device_name, device_name_len),
		};

		adv_param = *BT_LE_ADV_CONN_FAST_2;
		err = bt_le_adv_start(&adv_param, ad, ARRAY_SIZE(ad), sd, ARRAY_SIZE(sd));
		if (err) {
			printk("Advertising failed to start (err %d)\n", err);
			return;
		}

		printk("Regular advertising started\n");
	}

	is_adv_running = true;
}

static void advertising_start(void)
{
#if CONFIG_BT_DIRECTED_ADVERTISING
	k_msgq_purge(&bonds_queue);
	bt_foreach_bond(BT_ID_DEFAULT, bond_find, NULL);
#endif

	k_work_submit(&adv_work);
}

static void advertising_process(struct k_work *work)
{
	advertising_continue();
}

static void insert_conn_object(struct bt_conn *conn)
{
	for (size_t i = 0; i < CONFIG_BT_HIDS_MAX_CLIENT_COUNT; i++) {
		if (!connections[i]) {
			connections[i] = conn;
			return;
		}
	}

	printk("Connection object could not be inserted %p\n", conn);
}

static void remove_conn_object(struct bt_conn *conn)
{
	for (size_t i = 0; i < CONFIG_BT_HIDS_MAX_CLIENT_COUNT; i++) {
		if (connections[i] == conn) {
			connections[i] = NULL;
			break;
		}
	}
}

bool bluetooth_is_conn_slot_free(void)
{
	for (size_t i = 0; i < CONFIG_BT_HIDS_MAX_CLIENT_COUNT; i++) {
		if (!connections[i]) {
			return true;
		}
	}
	return false;
}

struct bt_conn *bluetooth_get_conn(size_t index)
{
	if (index < CONFIG_BT_HIDS_MAX_CLIENT_COUNT) {
		return connections[index];
	}
	return NULL;
}

static void connected(struct bt_conn *conn, uint8_t err)
{
	char addr[BT_ADDR_LE_STR_LEN];

	is_adv_running = false;
	bt_addr_le_to_str(bt_conn_get_dst(conn), addr, sizeof(addr));

	if (err) {
		if (err == BT_HCI_ERR_ADV_TIMEOUT) {
			printk("Direct advertising to %s timed out\n", addr);
			k_work_submit(&adv_work);
		} else {
			printk("Failed to connect to %s 0x%02x %s\n", 
			       addr, err, bt_hci_err_to_str(err));
		}
		return;
	}

	printk("Connected %s\n", addr);

	/* Notify HID service */
	err = hid_notify_connected(conn);
	if (err) {
		printk("Failed to notify HID service about connection\n");
		return;
	}

	insert_conn_object(conn);

	struct bt_conn_info info;
	bt_conn_get_info(conn, &info);
	
	printk("Initial connection parameters:\n");
	printk("  Interval: %u (%.2f ms)\n", 
	       info.le.interval, info.le.interval * 1.25);
	printk("  Latency: %u\n", info.le.latency);
	printk("  Timeout: %u\n", info.le.timeout);

	if (bluetooth_is_conn_slot_free()) {
		advertising_start();
	}
}

static void disconnected(struct bt_conn *conn, uint8_t reason)
{
	char addr[BT_ADDR_LE_STR_LEN];

	bt_addr_le_to_str(bt_conn_get_dst(conn), addr, sizeof(addr));
	printk("Disconnected from %s, reason 0x%02x %s\n", 
	       addr, reason, bt_hci_err_to_str(reason));


	is_security_passed = false;

	/* Notify HID service */
	int err = hid_notify_disconnected(conn);
	if (err) {
		printk("Failed to notify HID service about disconnection\n");
	}

	remove_conn_object(conn);
	advertising_start();
}

#ifdef CONFIG_BT_HIDS_SECURITY_ENABLED
static void security_changed(struct bt_conn *conn, bt_security_t level,
			     enum bt_security_err err)
{
	char addr[BT_ADDR_LE_STR_LEN];

	bt_addr_le_to_str(bt_conn_get_dst(conn), addr, sizeof(addr));

	if (!err) {
		printk("Security changed: %s level %u\n", addr, level);
		is_security_passed = true;

	} else {
		printk("Security failed: %s level %u err %d %s\n", 
		       addr, level, err, bt_security_err_to_str(err));
		is_security_passed = false;
	}
}
#endif

BT_CONN_CB_DEFINE(conn_callbacks) = {
	.connected = connected,
	.disconnected = disconnected,
#ifdef CONFIG_BT_HIDS_SECURITY_ENABLED
	.security_changed = security_changed,
#endif
};

/* Authentication callbacks */
#if defined(CONFIG_BT_HIDS_SECURITY_ENABLED)
static void auth_passkey_display(struct bt_conn *conn, unsigned int passkey)
{
	char addr[BT_ADDR_LE_STR_LEN];

	bt_addr_le_to_str(bt_conn_get_dst(conn), addr, sizeof(addr));
	printk("Passkey for %s: %06u\n", addr, passkey);
}

static void auth_passkey_confirm(struct bt_conn *conn, unsigned int passkey)
{
	char addr[BT_ADDR_LE_STR_LEN];

	bt_addr_le_to_str(bt_conn_get_dst(conn), addr, sizeof(addr));
	printk("Auto-accepting pairing for %s: %06u\n", addr, passkey);
	
	bt_conn_auth_passkey_confirm(conn);
}

static void auth_cancel(struct bt_conn *conn)
{
	char addr[BT_ADDR_LE_STR_LEN];

	bt_addr_le_to_str(bt_conn_get_dst(conn), addr, sizeof(addr));
	printk("Pairing cancelled: %s\n", addr);
}

static void pairing_complete(struct bt_conn *conn, bool bonded)
{
	char addr[BT_ADDR_LE_STR_LEN];

	bt_addr_le_to_str(bt_conn_get_dst(conn), addr, sizeof(addr));
	printk("Pairing completed: %s, bonded: %d\n", addr, bonded);
}

static void pairing_failed(struct bt_conn *conn, enum bt_security_err reason)
{
	char addr[BT_ADDR_LE_STR_LEN];

	bt_addr_le_to_str(bt_conn_get_dst(conn), addr, sizeof(addr));
	printk("Pairing failed conn: %s, reason %d %s\n", 
	       addr, reason, bt_security_err_to_str(reason));
}

static struct bt_conn_auth_cb conn_auth_callbacks = {
	.passkey_display = auth_passkey_display,
	.passkey_confirm = auth_passkey_confirm,
	.cancel = auth_cancel,
};

static struct bt_conn_auth_info_cb conn_auth_info_callbacks = {
	.pairing_complete = pairing_complete,
	.pairing_failed = pairing_failed
};
#else
static struct bt_conn_auth_cb conn_auth_callbacks;
static struct bt_conn_auth_info_cb conn_auth_info_callbacks;
#endif

int bluetooth_init(const char *name)
{
	int err;

	device_name = name;
	device_name_len = strlen(name);

	/* Register authentication callbacks */
	if (IS_ENABLED(CONFIG_BT_HIDS_SECURITY_ENABLED)) {
		err = bt_conn_auth_cb_register(&conn_auth_callbacks);
		if (err) {
			printk("Failed to register authorization callbacks.\n");
			return err;
		}

		err = bt_conn_auth_info_cb_register(&conn_auth_info_callbacks);
		if (err) {
			printk("Failed to register authorization info callbacks.\n");
			return err;
		}
	}

	/* Enable Bluetooth */
	err = bt_enable(NULL);
	if (err) {
		printk("Bluetooth init failed (err %d)\n", err);
		return err;
	}

	printk("Bluetooth initialized\n");

	/* Initialize work queues */
	k_work_init(&adv_work, advertising_process);

	/* Load settings if enabled */
	if (IS_ENABLED(CONFIG_SETTINGS)) {
		settings_load();
	}

	/* Start advertising */
	advertising_start();

	return 0;
}

bool bluetooth_security_passed(void)
{
	return is_security_passed;
}
```

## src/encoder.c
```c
/**
 * @file encoder.c
 * @brief MT6701 Magnetic Encoder via I2C (Dual encoder support)
 * 
 * Tracks absolute offset from initial reference position.
 * The further the encoder is turned from its starting position,
 * the larger the delta value returned.
 */

#include "encoder.h"
#include <zephyr/kernel.h>
#include <zephyr/device.h>
#include <zephyr/drivers/i2c.h>
#include <zephyr/drivers/gpio.h>
#include <errno.h>

/* MT6701 I2C Configuration */
#define MT6701_I2C_ADDR         0x06
#define MT6701_ANGLE_REG_H      0x03
#define MT6701_ANGLE_REG_L      0x04
#define MT6701_RESOLUTION       16384  // 14-bit: 2^14 = 16384
#define MT6701_HALF_RESOLUTION  8192   // For wraparound detection

/* LED for debugging */
#define LED_NODE DT_ALIAS(led0)
static const struct gpio_dt_spec led = GPIO_DT_SPEC_GET(LED_NODE, gpios);

/* I2C devices */
static const struct device *i2c_dev_0;
static const struct device *i2c_dev_1;

/* Encoder 0 state (i2c0) */
static uint16_t reference_angle_0 = 0;
static bool initialized_0 = false;

/* Encoder 1 state (i2c1) */
static uint16_t reference_angle_1 = 0;
static bool initialized_1 = false;

/**
 * @brief Read 14-bit angle from MT6701 via I2C
 */
static int mt6701_read_angle(const struct device *i2c_dev, uint16_t *angle)
{
    uint8_t data[2];
    int ret;

    if (!angle || !i2c_dev) {
        return -EINVAL;
    }

    ret = i2c_burst_read(i2c_dev, MT6701_I2C_ADDR, MT6701_ANGLE_REG_H, data, 2);
    if (ret < 0) {
        return ret;
    }

    *angle = ((uint16_t)data[0] << 6) | (data[1] >> 2);
    *angle &= 0x3FFF;

    return 0;
}

/**
 * @brief Calculate signed offset from reference, handling wraparound
 */
static int32_t calculate_offset(uint16_t current, uint16_t reference)
{
    int32_t offset = (int32_t)current - (int32_t)reference;

    /* Handle wraparound */
    if (offset > MT6701_HALF_RESOLUTION) {
        offset -= MT6701_RESOLUTION;
    } else if (offset < -MT6701_HALF_RESOLUTION) {
        offset += MT6701_RESOLUTION;
    }

    return offset;
}

/**
 * @brief Initialize both MT6701 encoders
 * 
 * Saves current positions as reference points.
 */
int encoder_init(void)
{
    int ret;

    /* Initialize LED for debugging */
    if (device_is_ready(led.port)) {
        gpio_pin_configure_dt(&led, GPIO_OUTPUT_INACTIVE);
    }

    /* Initialize encoder 0 on I2C0 */
    i2c_dev_0 = DEVICE_DT_GET(DT_NODELABEL(i2c0));
    if (!device_is_ready(i2c_dev_0)) {
        printk("Encoder 0: I2C0 device not ready\n");
        return -ENODEV;
    }

    ret = mt6701_read_angle(i2c_dev_0, &reference_angle_0);
    if (ret < 0) {
        printk("Encoder 0: Failed to read reference angle (err %d)\n", ret);
        return ret;
    }
    initialized_0 = true;
    printk("Encoder 0: Initialized, reference = %u\n", reference_angle_0);


    /* Initialize encoder 1 on I2C1 */

    i2c_dev_1 = DEVICE_DT_GET(DT_NODELABEL(i2c1));
    if (!device_is_ready(i2c_dev_1)) {
        printk("Encoder 1: I2C1 device not ready\n");
        return -ENODEV;
    }

    ret = mt6701_read_angle(i2c_dev_1, &reference_angle_1);
    if (ret < 0) {
        printk("Encoder 1: Failed to read reference angle (err %d)\n", ret);
        return ret;
    }
    initialized_1 = true;
    printk("Encoder 1: Initialized, reference = %u\n", reference_angle_1);

    return 0;
}

/**
 * @brief Read offset from reference for encoder 0
 */
int encoder_read_delta_0(int32_t *delta)
{
    uint16_t current_angle;
    int ret;

    if (!delta) {
        return -EINVAL;
    }

    if (!initialized_0) {
        *delta = 0;
        return -ENODEV;
    }

    ret = mt6701_read_angle(i2c_dev_0, &current_angle);
    if (ret < 0) {
        *delta = 0;
        return ret;
    }

    *delta = calculate_offset(current_angle, reference_angle_0);
   
    return 0;
}

/**
 * @brief Read offset from reference for encoder 1
 */
int encoder_read_delta_1(int32_t *delta)
{
    uint16_t current_angle;
    int ret;

    if (!delta) {
        return -EINVAL;
    }

    if (!initialized_1) {
        *delta = 0;
        return -ENODEV;
    }

    ret = mt6701_read_angle(i2c_dev_1, &current_angle);
    if (ret < 0) {
        *delta = 0;
        return ret;
    }

    *delta = calculate_offset(current_angle, reference_angle_1);
 
    return 0;
}

/**
 * @brief Read combined offset from both encoders
 */
int encoder_read_delta(int32_t *delta)
{
    int32_t delta_0 = 0;
    int32_t delta_1 = 0;

    if (!delta) {
        return -EINVAL;
    }

    encoder_read_delta_0(&delta_0);
    encoder_read_delta_1(&delta_1);

    *delta = delta_0 + delta_1;

    /* LED feedback */
    if (*delta != 0 && device_is_ready(led.port)) {
        gpio_pin_toggle_dt(&led);
    }

    return 0;
}

/**
 * @brief Reset encoder 0 reference to current position
 */
int encoder_reset_reference_0(void)
{
    if (!initialized_0) {
        return -ENODEV;
    }
    return mt6701_read_angle(i2c_dev_0, &reference_angle_0);
}

/**
 * @brief Reset encoder 1 reference to current position
 */
int encoder_reset_reference_1(void)
{
    if (!initialized_1) {
        return -ENODEV;
    }
    return mt6701_read_angle(i2c_dev_1, &reference_angle_1);
}
```

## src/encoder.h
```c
/**
 * @file encoder.h
 * @brief Rotary Encoder Hardware Abstraction
 */

#ifndef ENCODER_H
#define ENCODER_H

#include <stdint.h>

int encoder_init(void);
int encoder_read_delta(int32_t *delta);

#endif /* ENCODER_H */
```

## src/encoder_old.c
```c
/**
 * @file encoder.c
 * @brief MT6701 Magnetic Encoder via I2C (Dual encoder support)
 */

#include "encoder.h"
#include <zephyr/kernel.h>
#include <zephyr/device.h>
#include <zephyr/drivers/i2c.h>
#include <zephyr/drivers/gpio.h>
#include <errno.h>

/* MT6701 I2C Configuration */
#define MT6701_I2C_ADDR         0x06
#define MT6701_ANGLE_REG_H      0x03  // Angle high byte register
#define MT6701_ANGLE_REG_L      0x04  // Angle low byte register
#define MT6701_RESOLUTION       16384  // 14-bit: 2^14 = 16384
#define MT6701_HALF_RESOLUTION  8192   // For wraparound detection

/* Sensitivity tuning - adjust this to taste! */
#define SCROLL_SCALING_FACTOR   10  // Lower = more sensitive
#define DEAD_ZONE_FACTOR   10  // Lower = more sensitive


/* LED for debugging */
#define LED_NODE DT_ALIAS(led0)
static const struct gpio_dt_spec led = GPIO_DT_SPEC_GET(LED_NODE, gpios);

/* I2C devices */
static const struct device *i2c_dev_0;
static const struct device *i2c_dev_1;

/* Encoder 0 state (i2c0) */
static uint16_t last_angle_0 = 0;
static int32_t accumulated_0 = 0;
static bool initialized_0 = false;

/* Encoder 1 state (i2c1) */
static uint16_t last_angle_1 = 0;
static int32_t accumulated_1 = 0;
static bool initialized_1 = false;

/**
 * @brief Read 14-bit angle from MT6701 via I2C
 * 
 * @param i2c_dev I2C device to use
 * @param angle Pointer to store angle value (0-16383)
 * @return 0 on success, negative errno on failure
 */
static int mt6701_read_angle(const struct device *i2c_dev, uint16_t *angle)
{
    uint8_t data[2];
    int ret;

    if (!angle || !i2c_dev) {
        return -EINVAL;
    }

    /* Read 2 bytes starting from angle high register */
    ret = i2c_burst_read(i2c_dev, MT6701_I2C_ADDR, MT6701_ANGLE_REG_H, data, 2);
    if (ret < 0) {
        return ret;
    }

    /* 
     * Combine bytes into 14-bit angle
     * MT6701 format: [13:6] in high byte, [5:0] in low byte bits [7:2]
     * High byte has bits 13-6 (8 bits)
     * Low byte has bits 5-0 in positions [7:2], shift right by 2
     */
    *angle = ((uint16_t)data[0] << 6) | (data[1] >> 2);
    
    /* Ensure angle is within valid range */
    *angle &= 0x3FFF;  // Mask to 14 bits (0-16383)

    return 0;
}

/**
 * @brief Initialize both MT6701 encoders
 * 
 * Sets up I2C communication and reads initial positions
 * 
 * @return 0 on success, negative errno on failure
 */
int encoder_init(void)
{
    int ret;

    /* Initialize LED for debugging */
    if (device_is_ready(led.port)) {
        gpio_pin_configure_dt(&led, GPIO_OUTPUT_INACTIVE);
    }

    /* Get I2C0 device (encoder 0) */
    i2c_dev_0 = DEVICE_DT_GET(DT_NODELABEL(i2c0));
    if (!device_is_ready(i2c_dev_0)) {
        printk("Encoder 0: I2C0 device not ready\n");
        return -ENODEV;
    }

    /* Read initial angle for encoder 0 */
    ret = mt6701_read_angle(i2c_dev_0, &last_angle_0);
    if (ret < 0) {
        printk("Encoder 0: Failed to read initial angle (err %d)\n", ret);
        return ret;
    }
    initialized_0 = true;
    printk("Encoder 0: Initialized on I2C0\n");

    /* Get I2C1 device (encoder 1) */
    i2c_dev_1 = DEVICE_DT_GET(DT_NODELABEL(i2c1));
    if (!device_is_ready(i2c_dev_1)) {
        printk("Encoder 1: I2C1 device not ready\n");
        return -ENODEV;
    }

    /* Read initial angle for encoder 1 */
    ret = mt6701_read_angle(i2c_dev_1, &last_angle_1);
    if (ret < 0) {
        printk("Encoder 1: Failed to read initial angle (err %d)\n", ret);
        return ret;
    }
    initialized_1 = true;
    printk("Encoder 1: Initialized on I2C1\n");

    return 0;
}

/**
 * @brief Read delta from encoder 0
 */
int encoder_read_delta_0(int32_t *delta)
{
    uint16_t current_angle;
    int32_t raw_delta;
    int ret;

    if (!delta) {
        return -EINVAL;
    }

    if (!initialized_0) {
        *delta = 0;
        return -ENODEV;
    }

    ret = mt6701_read_angle(i2c_dev_0, &current_angle);
    if (ret < 0) {
        *delta = 0;
        return ret;
    }

    /* Calculate delta */
    raw_delta = (int32_t)current_angle - (int32_t)last_angle_0;

    /* Handle wraparound */
    if (raw_delta > MT6701_HALF_RESOLUTION) {
        raw_delta -= MT6701_RESOLUTION;
    } else if (raw_delta < -MT6701_HALF_RESOLUTION) {
        raw_delta += MT6701_RESOLUTION;
    }

    /* Accumulate movement */
    accumulated_0 += raw_delta;
    
    *delta = accumulated_0 / SCROLL_SCALING_FACTOR;
    accumulated_0 -= (*delta * SCROLL_SCALING_FACTOR);

    last_angle_0 = current_angle;
    if (*delta <= DEAD_ZONE_FACTOR) {
        *delta = 0;
    }
    return 0;
}

/**
 * @brief Read delta from encoder 1
 */
int encoder_read_delta_1(int32_t *delta)
{
    uint16_t current_angle;
    int32_t raw_delta;
    int ret;

    if (!delta) {
        return -EINVAL;
    }

    if (!initialized_1) {
        *delta = 0;
        return -ENODEV;
    }

    ret = mt6701_read_angle(i2c_dev_1, &current_angle);
    if (ret < 0) {
        *delta = 0;
        return ret;
    }

    /* Calculate delta */
    raw_delta = (int32_t)current_angle - (int32_t)last_angle_1;

    /* Handle wraparound */
    if (raw_delta > MT6701_HALF_RESOLUTION) {
        raw_delta -= MT6701_RESOLUTION;
    } else if (raw_delta < -MT6701_HALF_RESOLUTION) {
        raw_delta += MT6701_RESOLUTION;
    }

    /* Accumulate movement */
    accumulated_1 += raw_delta;
    
    *delta = accumulated_1 / SCROLL_SCALING_FACTOR;
    accumulated_1 -= (*delta * SCROLL_SCALING_FACTOR);

    last_angle_1 = current_angle;
    if (*delta <= DEAD_ZONE_FACTOR) {
        *delta = 0;
    }
    return 0;
}

/**
 * @brief Read combined delta from both encoders (legacy compatibility)
 * 
 * Reads both encoders and returns their combined delta.
 * Also toggles LED on any movement.
 */
int encoder_read_delta(int32_t *delta)
{
    int32_t delta_0 = 0;
    int32_t delta_1 = 0;

    if (!delta) {
        return -EINVAL;
    }

    /* Read both encoders - don't fail if one is missing */
    encoder_read_delta_0(&delta_0);
    encoder_read_delta_1(&delta_1);

    /* Combine deltas */
    *delta = delta_0 + delta_1;

    /* LED feedback */
    if (*delta != 0 && device_is_ready(led.port)) {
        gpio_pin_toggle_dt(&led);
    }

    return 0;
}
```
